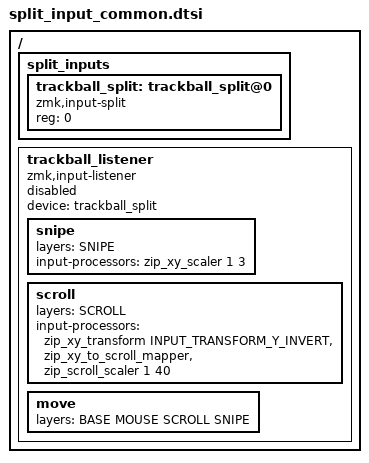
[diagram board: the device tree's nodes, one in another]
#include <dt-bindings/zmk/input_transform.h>
#include <input/processors.dtsi>

#define BASE 0
#define MOUSE 1
#define SCROLL 2
#define SNIPE 3
#define NO_HRM 4
#define LEFT_NUMS 5
#define RIGHT_NUMS 6

/ {
  split_inputs {
    #address-cells = <1>;
    #size-cells = <0>;

    trackball_split: trackball_split@0 {
      compatible = "zmk,input-split";
      reg = <0>;
    };
  };

  trackball_listener: trackball_listener {
    compatible = "zmk,input-listener";
    status = "disabled";
    device = <&trackball_split>;

     snipe {
       layers = <SNIPE>;
       input-processors = <&zip_xy_scaler 1 3>;
     };

    scroll {
      layers = <SCROLL>;
      input-processors =
          <&zip_xy_transform INPUT_TRANSFORM_Y_INVERT>,
          <&zip_xy_to_scroll_mapper>,
          <&zip_scroll_scaler 1 40>;
    };

    move {
      layers = <BASE MOUSE SCROLL SNIPE>;
    };
  };
};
